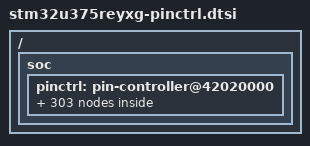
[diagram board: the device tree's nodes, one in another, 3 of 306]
/*
 * NOTE: Autogenerated file using genpinctrl.py
 *
 * SPDX-License-Identifier: Apache-2.0
 */

#include <zephyr/dt-bindings/pinctrl/stm32-pinctrl.h>

/ {
	soc {
		pinctrl: pin-controller@42020000 {

			/* ADC_IN / ADC_INN / ADC_INP */

			/omit-if-no-ref/ adc1_in3_pa0: adc1_in3_pa0 {
				pinmux = <STM32_PINMUX('A', 0, ANALOG)>;
			};

			/omit-if-no-ref/ adc1_in4_pa1: adc1_in4_pa1 {
				pinmux = <STM32_PINMUX('A', 1, ANALOG)>;
			};

			/omit-if-no-ref/ adc1_in5_pa2: adc1_in5_pa2 {
				pinmux = <STM32_PINMUX('A', 2, ANALOG)>;
			};

			/omit-if-no-ref/ adc1_in6_pa3: adc1_in6_pa3 {
				pinmux = <STM32_PINMUX('A', 3, ANALOG)>;
			};

			/omit-if-no-ref/ adc1_in7_pa4: adc1_in7_pa4 {
				pinmux = <STM32_PINMUX('A', 4, ANALOG)>;
			};

			/omit-if-no-ref/ adc1_in8_pa5: adc1_in8_pa5 {
				pinmux = <STM32_PINMUX('A', 5, ANALOG)>;
			};

			/omit-if-no-ref/ adc1_in9_pa6: adc1_in9_pa6 {
				pinmux = <STM32_PINMUX('A', 6, ANALOG)>;
			};

			/omit-if-no-ref/ adc1_in10_pa7: adc1_in10_pa7 {
				pinmux = <STM32_PINMUX('A', 7, ANALOG)>;
			};

			/omit-if-no-ref/ adc1_in13_pb0: adc1_in13_pb0 {
				pinmux = <STM32_PINMUX('B', 0, ANALOG)>;
			};

			/omit-if-no-ref/ adc1_in14_pb1: adc1_in14_pb1 {
				pinmux = <STM32_PINMUX('B', 1, ANALOG)>;
			};

			/omit-if-no-ref/ adc1_in15_pb2: adc1_in15_pb2 {
				pinmux = <STM32_PINMUX('B', 2, ANALOG)>;
			};

			/omit-if-no-ref/ adc2_in3_pa4: adc2_in3_pa4 {
				pinmux = <STM32_PINMUX('A', 4, ANALOG)>;
			};

			/omit-if-no-ref/ adc2_in4_pa5: adc2_in4_pa5 {
				pinmux = <STM32_PINMUX('A', 5, ANALOG)>;
			};

			/omit-if-no-ref/ adc2_in5_pa6: adc2_in5_pa6 {
				pinmux = <STM32_PINMUX('A', 6, ANALOG)>;
			};

			/omit-if-no-ref/ adc2_in6_pa7: adc2_in6_pa7 {
				pinmux = <STM32_PINMUX('A', 7, ANALOG)>;
			};

			/omit-if-no-ref/ adc2_in9_pb0: adc2_in9_pb0 {
				pinmux = <STM32_PINMUX('B', 0, ANALOG)>;
			};

			/omit-if-no-ref/ adc2_in10_pb1: adc2_in10_pb1 {
				pinmux = <STM32_PINMUX('B', 1, ANALOG)>;
			};

			/* Analog */

			/omit-if-no-ref/ analog_pa0: analog_pa0 {
				pinmux = <STM32_PINMUX('A', 0, ANALOG)>;
			};

			/omit-if-no-ref/ analog_pa1: analog_pa1 {
				pinmux = <STM32_PINMUX('A', 1, ANALOG)>;
			};

			/omit-if-no-ref/ analog_pa2: analog_pa2 {
				pinmux = <STM32_PINMUX('A', 2, ANALOG)>;
			};

			/omit-if-no-ref/ analog_pa3: analog_pa3 {
				pinmux = <STM32_PINMUX('A', 3, ANALOG)>;
			};

			/omit-if-no-ref/ analog_pa4: analog_pa4 {
				pinmux = <STM32_PINMUX('A', 4, ANALOG)>;
			};

			/omit-if-no-ref/ analog_pa5: analog_pa5 {
				pinmux = <STM32_PINMUX('A', 5, ANALOG)>;
			};

			/omit-if-no-ref/ analog_pa6: analog_pa6 {
				pinmux = <STM32_PINMUX('A', 6, ANALOG)>;
			};

			/omit-if-no-ref/ analog_pa7: analog_pa7 {
				pinmux = <STM32_PINMUX('A', 7, ANALOG)>;
			};

			/omit-if-no-ref/ analog_pa8: analog_pa8 {
				pinmux = <STM32_PINMUX('A', 8, ANALOG)>;
			};

			/omit-if-no-ref/ analog_pa9: analog_pa9 {
				pinmux = <STM32_PINMUX('A', 9, ANALOG)>;
			};

			/omit-if-no-ref/ analog_pa10: analog_pa10 {
				pinmux = <STM32_PINMUX('A', 10, ANALOG)>;
			};

			/omit-if-no-ref/ analog_pa11: analog_pa11 {
				pinmux = <STM32_PINMUX('A', 11, ANALOG)>;
			};

			/omit-if-no-ref/ analog_pa12: analog_pa12 {
				pinmux = <STM32_PINMUX('A', 12, ANALOG)>;
			};

			/omit-if-no-ref/ analog_pa13: analog_pa13 {
				pinmux = <STM32_PINMUX('A', 13, ANALOG)>;
			};

			/omit-if-no-ref/ analog_pa14: analog_pa14 {
				pinmux = <STM32_PINMUX('A', 14, ANALOG)>;
			};

			/omit-if-no-ref/ analog_pa15: analog_pa15 {
				pinmux = <STM32_PINMUX('A', 15, ANALOG)>;
			};

			/omit-if-no-ref/ analog_pb0: analog_pb0 {
				pinmux = <STM32_PINMUX('B', 0, ANALOG)>;
			};

			/omit-if-no-ref/ analog_pb1: analog_pb1 {
				pinmux = <STM32_PINMUX('B', 1, ANALOG)>;
			};

			/omit-if-no-ref/ analog_pb2: analog_pb2 {
				pinmux = <STM32_PINMUX('B', 2, ANALOG)>;
			};

			/omit-if-no-ref/ analog_pb3: analog_pb3 {
				pinmux = <STM32_PINMUX('B', 3, ANALOG)>;
			};

			/omit-if-no-ref/ analog_pb4: analog_pb4 {
				pinmux = <STM32_PINMUX('B', 4, ANALOG)>;
			};

			/omit-if-no-ref/ analog_pb5: analog_pb5 {
				pinmux = <STM32_PINMUX('B', 5, ANALOG)>;
			};

			/omit-if-no-ref/ analog_pb6: analog_pb6 {
				pinmux = <STM32_PINMUX('B', 6, ANALOG)>;
			};

			/omit-if-no-ref/ analog_pb7: analog_pb7 {
				pinmux = <STM32_PINMUX('B', 7, ANALOG)>;
			};

			/omit-if-no-ref/ analog_pb13: analog_pb13 {
				pinmux = <STM32_PINMUX('B', 13, ANALOG)>;
			};

			/omit-if-no-ref/ analog_pb14: analog_pb14 {
				pinmux = <STM32_PINMUX('B', 14, ANALOG)>;
			};

			/omit-if-no-ref/ analog_pb15: analog_pb15 {
				pinmux = <STM32_PINMUX('B', 15, ANALOG)>;
			};

			/omit-if-no-ref/ analog_pc13: analog_pc13 {
				pinmux = <STM32_PINMUX('C', 13, ANALOG)>;
			};

			/omit-if-no-ref/ analog_pc14: analog_pc14 {
				pinmux = <STM32_PINMUX('C', 14, ANALOG)>;
			};

			/omit-if-no-ref/ analog_pc15: analog_pc15 {
				pinmux = <STM32_PINMUX('C', 15, ANALOG)>;
			};

			/omit-if-no-ref/ analog_pg2: analog_pg2 {
				pinmux = <STM32_PINMUX('G', 2, ANALOG)>;
			};

			/omit-if-no-ref/ analog_pg3: analog_pg3 {
				pinmux = <STM32_PINMUX('G', 3, ANALOG)>;
			};

			/omit-if-no-ref/ analog_pg4: analog_pg4 {
				pinmux = <STM32_PINMUX('G', 4, ANALOG)>;
			};

			/omit-if-no-ref/ analog_pg5: analog_pg5 {
				pinmux = <STM32_PINMUX('G', 5, ANALOG)>;
			};

			/omit-if-no-ref/ analog_pg6: analog_pg6 {
				pinmux = <STM32_PINMUX('G', 6, ANALOG)>;
			};

			/omit-if-no-ref/ analog_pg7: analog_pg7 {
				pinmux = <STM32_PINMUX('G', 7, ANALOG)>;
			};

			/omit-if-no-ref/ analog_pg8: analog_pg8 {
				pinmux = <STM32_PINMUX('G', 8, ANALOG)>;
			};

			/omit-if-no-ref/ analog_pg9: analog_pg9 {
				pinmux = <STM32_PINMUX('G', 9, ANALOG)>;
			};

			/omit-if-no-ref/ analog_pg10: analog_pg10 {
				pinmux = <STM32_PINMUX('G', 10, ANALOG)>;
			};

			/omit-if-no-ref/ analog_pg11: analog_pg11 {
				pinmux = <STM32_PINMUX('G', 11, ANALOG)>;
			};

			/omit-if-no-ref/ analog_pg12: analog_pg12 {
				pinmux = <STM32_PINMUX('G', 12, ANALOG)>;
			};

			/omit-if-no-ref/ analog_pg13: analog_pg13 {
				pinmux = <STM32_PINMUX('G', 13, ANALOG)>;
			};

			/omit-if-no-ref/ analog_pg14: analog_pg14 {
				pinmux = <STM32_PINMUX('G', 14, ANALOG)>;
			};

			/omit-if-no-ref/ analog_pg15: analog_pg15 {
				pinmux = <STM32_PINMUX('G', 15, ANALOG)>;
			};

			/omit-if-no-ref/ analog_ph0: analog_ph0 {
				pinmux = <STM32_PINMUX('H', 0, ANALOG)>;
			};

			/omit-if-no-ref/ analog_ph1: analog_ph1 {
				pinmux = <STM32_PINMUX('H', 1, ANALOG)>;
			};

			/omit-if-no-ref/ analog_ph3: analog_ph3 {
				pinmux = <STM32_PINMUX('H', 3, ANALOG)>;
			};

			/* COMP_IN */

			/omit-if-no-ref/ comp1_inp_pa2: comp1_inp_pa2 {
				pinmux = <STM32_PINMUX('A', 2, ANALOG)>;
			};

			/omit-if-no-ref/ comp1_inp_pa3: comp1_inp_pa3 {
				pinmux = <STM32_PINMUX('A', 3, ANALOG)>;
			};

			/omit-if-no-ref/ comp1_inm_pb1: comp1_inm_pb1 {
				pinmux = <STM32_PINMUX('B', 1, ANALOG)>;
			};

			/omit-if-no-ref/ comp1_inp_pb2: comp1_inp_pb2 {
				pinmux = <STM32_PINMUX('B', 2, ANALOG)>;
			};

			/omit-if-no-ref/ comp2_inm_pb3: comp2_inm_pb3 {
				pinmux = <STM32_PINMUX('B', 3, ANALOG)>;
			};

			/omit-if-no-ref/ comp2_inp_pb4: comp2_inp_pb4 {
				pinmux = <STM32_PINMUX('B', 4, ANALOG)>;
			};

			/omit-if-no-ref/ comp2_inp_pb6: comp2_inp_pb6 {
				pinmux = <STM32_PINMUX('B', 6, ANALOG)>;
			};

			/omit-if-no-ref/ comp2_inm_pb7: comp2_inm_pb7 {
				pinmux = <STM32_PINMUX('B', 7, ANALOG)>;
			};

			/* COMP_OUT */

			/omit-if-no-ref/ comp1_out_pb0: comp1_out_pb0 {
				pinmux = <STM32_PINMUX('B', 0, AF12)>;
			};

			/omit-if-no-ref/ comp2_out_pb5: comp2_out_pb5 {
				pinmux = <STM32_PINMUX('B', 5, AF12)>;
			};

			/* DAC_OUT */

			/omit-if-no-ref/ dac1_out1_pa4: dac1_out1_pa4 {
				pinmux = <STM32_PINMUX('A', 4, ANALOG)>;
			};

			/omit-if-no-ref/ dac1_out2_pa5: dac1_out2_pa5 {
				pinmux = <STM32_PINMUX('A', 5, ANALOG)>;
			};

			/* FDCAN_RX */

			/omit-if-no-ref/ fdcan1_rx_pa11: fdcan1_rx_pa11 {
				pinmux = <STM32_PINMUX('A', 11, AF9)>;
			};

			/* FDCAN_TX */

			/omit-if-no-ref/ fdcan1_tx_pa12: fdcan1_tx_pa12 {
				pinmux = <STM32_PINMUX('A', 12, AF9)>;
			};

			/* I2C_SCL */

			/omit-if-no-ref/ i2c1_scl_pb6: i2c1_scl_pb6 {
				pinmux = <STM32_PINMUX('B', 6, AF4)>;
				bias-pull-up;
				drive-open-drain;
			};

			/omit-if-no-ref/ i2c1_scl_pg14: i2c1_scl_pg14 {
				pinmux = <STM32_PINMUX('G', 14, AF4)>;
				bias-pull-up;
				drive-open-drain;
			};

			/omit-if-no-ref/ i2c2_scl_pb2: i2c2_scl_pb2 {
				pinmux = <STM32_PINMUX('B', 2, AF3)>;
				bias-pull-up;
				drive-open-drain;
			};

			/omit-if-no-ref/ i2c2_scl_pb13: i2c2_scl_pb13 {
				pinmux = <STM32_PINMUX('B', 13, AF4)>;
				bias-pull-up;
				drive-open-drain;
			};

			/omit-if-no-ref/ i2c3_scl_pa7: i2c3_scl_pa7 {
				pinmux = <STM32_PINMUX('A', 7, AF4)>;
				bias-pull-up;
				drive-open-drain;
			};

			/omit-if-no-ref/ i2c3_scl_pg7: i2c3_scl_pg7 {
				pinmux = <STM32_PINMUX('G', 7, AF4)>;
				bias-pull-up;
				drive-open-drain;
			};

			/* I2C_SDA */

			/omit-if-no-ref/ i2c1_sda_pb3: i2c1_sda_pb3 {
				pinmux = <STM32_PINMUX('B', 3, AF4)>;
				bias-pull-up;
				drive-open-drain;
			};

			/omit-if-no-ref/ i2c1_sda_pb7: i2c1_sda_pb7 {
				pinmux = <STM32_PINMUX('B', 7, AF4)>;
				bias-pull-up;
				drive-open-drain;
			};

			/omit-if-no-ref/ i2c1_sda_pg13: i2c1_sda_pg13 {
				pinmux = <STM32_PINMUX('G', 13, AF4)>;
				bias-pull-up;
				drive-open-drain;
			};

			/omit-if-no-ref/ i2c2_sda_pa6: i2c2_sda_pa6 {
				pinmux = <STM32_PINMUX('A', 6, AF4)>;
				bias-pull-up;
				drive-open-drain;
			};

			/omit-if-no-ref/ i2c2_sda_pb14: i2c2_sda_pb14 {
				pinmux = <STM32_PINMUX('B', 14, AF4)>;
				bias-pull-up;
				drive-open-drain;
			};

			/omit-if-no-ref/ i2c3_sda_pb4: i2c3_sda_pb4 {
				pinmux = <STM32_PINMUX('B', 4, AF4)>;
				bias-pull-up;
				drive-open-drain;
			};

			/omit-if-no-ref/ i2c3_sda_pg8: i2c3_sda_pg8 {
				pinmux = <STM32_PINMUX('G', 8, AF4)>;
				bias-pull-up;
				drive-open-drain;
			};

			/* I2C_SMBA */

			/omit-if-no-ref/ i2c1_smba_pa1: i2c1_smba_pa1 {
				pinmux = <STM32_PINMUX('A', 1, AF4)>;
				bias-pull-up;
			};

			/omit-if-no-ref/ i2c1_smba_pa14: i2c1_smba_pa14 {
				pinmux = <STM32_PINMUX('A', 14, AF4)>;
				bias-pull-up;
			};

			/omit-if-no-ref/ i2c1_smba_pb5: i2c1_smba_pb5 {
				pinmux = <STM32_PINMUX('B', 5, AF4)>;
				bias-pull-up;
			};

			/omit-if-no-ref/ i2c1_smba_pg15: i2c1_smba_pg15 {
				pinmux = <STM32_PINMUX('G', 15, AF4)>;
				bias-pull-up;
			};

			/omit-if-no-ref/ i2c2_smba_pa1: i2c2_smba_pa1 {
				pinmux = <STM32_PINMUX('A', 1, AF3)>;
				bias-pull-up;
			};

			/omit-if-no-ref/ i2c2_smba_pa14: i2c2_smba_pa14 {
				pinmux = <STM32_PINMUX('A', 14, AF3)>;
				bias-pull-up;
			};

			/omit-if-no-ref/ i2c3_smba_pa14: i2c3_smba_pa14 {
				pinmux = <STM32_PINMUX('A', 14, AF5)>;
				bias-pull-up;
			};

			/omit-if-no-ref/ i2c3_smba_pb2: i2c3_smba_pb2 {
				pinmux = <STM32_PINMUX('B', 2, AF4)>;
				bias-pull-up;
			};

			/omit-if-no-ref/ i2c3_smba_pg6: i2c3_smba_pg6 {
				pinmux = <STM32_PINMUX('G', 6, AF4)>;
				bias-pull-up;
			};

			/* I3C_SCL */

			/omit-if-no-ref/ i3c1_scl_pa7: i3c1_scl_pa7 {
				pinmux = <STM32_PINMUX('A', 7, AF6)>;
				slew-rate = "very-high-speed";
			};

			/omit-if-no-ref/ i3c1_scl_pb2: i3c1_scl_pb2 {
				pinmux = <STM32_PINMUX('B', 2, AF6)>;
				slew-rate = "very-high-speed";
			};

			/omit-if-no-ref/ i3c1_scl_pb6: i3c1_scl_pb6 {
				pinmux = <STM32_PINMUX('B', 6, AF5)>;
				slew-rate = "very-high-speed";
			};

			/omit-if-no-ref/ i3c1_scl_pb13: i3c1_scl_pb13 {
				pinmux = <STM32_PINMUX('B', 13, AF3)>;
				slew-rate = "very-high-speed";
			};

			/omit-if-no-ref/ i3c1_scl_pg7: i3c1_scl_pg7 {
				pinmux = <STM32_PINMUX('G', 7, AF5)>;
				slew-rate = "very-high-speed";
			};

			/omit-if-no-ref/ i3c2_scl_pb6: i3c2_scl_pb6 {
				pinmux = <STM32_PINMUX('B', 6, AF6)>;
				slew-rate = "very-high-speed";
			};

			/omit-if-no-ref/ i3c2_scl_pb13: i3c2_scl_pb13 {
				pinmux = <STM32_PINMUX('B', 13, AF6)>;
				slew-rate = "very-high-speed";
			};

			/omit-if-no-ref/ i3c2_scl_pg13: i3c2_scl_pg13 {
				pinmux = <STM32_PINMUX('G', 13, AF5)>;
				slew-rate = "very-high-speed";
			};

			/* I3C_SDA */

			/omit-if-no-ref/ i3c1_sda_pa1: i3c1_sda_pa1 {
				pinmux = <STM32_PINMUX('A', 1, AF6)>;
				slew-rate = "very-high-speed";
			};

			/omit-if-no-ref/ i3c1_sda_pa6: i3c1_sda_pa6 {
				pinmux = <STM32_PINMUX('A', 6, AF6)>;
				slew-rate = "very-high-speed";
			};

			/omit-if-no-ref/ i3c1_sda_pg8: i3c1_sda_pg8 {
				pinmux = <STM32_PINMUX('G', 8, AF5)>;
				slew-rate = "very-high-speed";
			};

			/omit-if-no-ref/ i3c1_sda_ph3: i3c1_sda_ph3 {
				pinmux = <STM32_PINMUX('H', 3, AF3)>;
				slew-rate = "very-high-speed";
			};

			/omit-if-no-ref/ i3c2_sda_pa6: i3c2_sda_pa6 {
				pinmux = <STM32_PINMUX('A', 6, AF3)>;
				slew-rate = "very-high-speed";
			};

			/omit-if-no-ref/ i3c2_sda_pb14: i3c2_sda_pb14 {
				pinmux = <STM32_PINMUX('B', 14, AF6)>;
				slew-rate = "very-high-speed";
			};

			/omit-if-no-ref/ i3c2_sda_pg14: i3c2_sda_pg14 {
				pinmux = <STM32_PINMUX('G', 14, AF5)>;
				slew-rate = "very-high-speed";
			};

			/omit-if-no-ref/ i3c2_sda_ph3: i3c2_sda_ph3 {
				pinmux = <STM32_PINMUX('H', 3, AF6)>;
				slew-rate = "very-high-speed";
			};

			/* JTAG PORT */

			/omit-if-no-ref/ debug_jtms_swdio_pa13: debug_jtms_swdio_pa13 {
				pinmux = <STM32_PINMUX('A', 13, AF0)>;
			};

			/omit-if-no-ref/ debug_jtck_swclk_pa14: debug_jtck_swclk_pa14 {
				pinmux = <STM32_PINMUX('A', 14, AF0)>;
			};

			/omit-if-no-ref/ debug_jtdi_pa15: debug_jtdi_pa15 {
				pinmux = <STM32_PINMUX('A', 15, AF0)>;
			};

			/omit-if-no-ref/ debug_jtdo_swo_pb3: debug_jtdo_swo_pb3 {
				pinmux = <STM32_PINMUX('B', 3, AF0)>;
			};

			/omit-if-no-ref/ debug_njtrst_pb4: debug_njtrst_pb4 {
				pinmux = <STM32_PINMUX('B', 4, AF0)>;
			};

			/* OCTOSPI */

			/omit-if-no-ref/ octospi1_dqs_pa1: octospi1_dqs_pa1 {
				pinmux = <STM32_PINMUX('A', 1, AF10)>;
				slew-rate = "very-high-speed";
			};

			/omit-if-no-ref/ octospi1_ncs_pa2: octospi1_ncs_pa2 {
				pinmux = <STM32_PINMUX('A', 2, AF10)>;
				slew-rate = "very-high-speed";
			};

			/omit-if-no-ref/ octospi1_clk_pa3: octospi1_clk_pa3 {
				pinmux = <STM32_PINMUX('A', 3, AF10)>;
				slew-rate = "very-high-speed";
			};

			/omit-if-no-ref/ octospi1_ncs_pa4: octospi1_ncs_pa4 {
				pinmux = <STM32_PINMUX('A', 4, AF3)>;
				slew-rate = "very-high-speed";
			};

			/omit-if-no-ref/ octospi1_io3_pa6: octospi1_io3_pa6 {
				pinmux = <STM32_PINMUX('A', 6, AF10)>;
				slew-rate = "very-high-speed";
			};

			/omit-if-no-ref/ octospi1_io2_pa7: octospi1_io2_pa7 {
				pinmux = <STM32_PINMUX('A', 7, AF10)>;
				slew-rate = "very-high-speed";
			};

			/omit-if-no-ref/ octospi1_io1_pb0: octospi1_io1_pb0 {
				pinmux = <STM32_PINMUX('B', 0, AF10)>;
				slew-rate = "very-high-speed";
			};

			/omit-if-no-ref/ octospi1_io0_pb1: octospi1_io0_pb1 {
				pinmux = <STM32_PINMUX('B', 1, AF10)>;
				slew-rate = "very-high-speed";
			};

			/omit-if-no-ref/ octospi1_dqs_pb2: octospi1_dqs_pb2 {
				pinmux = <STM32_PINMUX('B', 2, AF10)>;
				slew-rate = "very-high-speed";
			};

			/omit-if-no-ref/ octospi1_io4_pb4: octospi1_io4_pb4 {
				pinmux = <STM32_PINMUX('B', 4, AF10)>;
				slew-rate = "very-high-speed";
			};

			/omit-if-no-ref/ octospi1_nclk_pb5: octospi1_nclk_pb5 {
				pinmux = <STM32_PINMUX('B', 5, AF3)>;
				slew-rate = "very-high-speed";
			};

			/omit-if-no-ref/ octospi1_io5_pb6: octospi1_io5_pb6 {
				pinmux = <STM32_PINMUX('B', 6, AF10)>;
				slew-rate = "very-high-speed";
			};

			/omit-if-no-ref/ octospi1_io6_pb7: octospi1_io6_pb7 {
				pinmux = <STM32_PINMUX('B', 7, AF10)>;
				slew-rate = "very-high-speed";
			};

			/omit-if-no-ref/ octospi1_io3_pg2: octospi1_io3_pg2 {
				pinmux = <STM32_PINMUX('G', 2, AF10)>;
				slew-rate = "very-high-speed";
			};

			/omit-if-no-ref/ octospi1_io4_pg3: octospi1_io4_pg3 {
				pinmux = <STM32_PINMUX('G', 3, AF10)>;
				slew-rate = "very-high-speed";
			};

			/omit-if-no-ref/ octospi1_io0_pg4: octospi1_io0_pg4 {
				pinmux = <STM32_PINMUX('G', 4, AF10)>;
				slew-rate = "very-high-speed";
			};

			/omit-if-no-ref/ octospi1_io1_pg5: octospi1_io1_pg5 {
				pinmux = <STM32_PINMUX('G', 5, AF10)>;
				slew-rate = "very-high-speed";
			};

			/omit-if-no-ref/ octospi1_dqs_pg6: octospi1_dqs_pg6 {
				pinmux = <STM32_PINMUX('G', 6, AF3)>;
				slew-rate = "very-high-speed";
			};

			/omit-if-no-ref/ octospi1_io2_pg8: octospi1_io2_pg8 {
				pinmux = <STM32_PINMUX('G', 8, AF10)>;
				slew-rate = "very-high-speed";
			};

			/omit-if-no-ref/ octospi1_io6_pg9: octospi1_io6_pg9 {
				pinmux = <STM32_PINMUX('G', 9, AF10)>;
				slew-rate = "very-high-speed";
			};

			/omit-if-no-ref/ octospi1_io7_pg10: octospi1_io7_pg10 {
				pinmux = <STM32_PINMUX('G', 10, AF10)>;
				slew-rate = "very-high-speed";
			};

			/omit-if-no-ref/ octospi1_io5_pg11: octospi1_io5_pg11 {
				pinmux = <STM32_PINMUX('G', 11, AF3)>;
				slew-rate = "very-high-speed";
			};

			/omit-if-no-ref/ octospi1_ncs_pg12: octospi1_ncs_pg12 {
				pinmux = <STM32_PINMUX('G', 12, AF10)>;
				slew-rate = "very-high-speed";
			};

			/omit-if-no-ref/ octospi1_clk_pg13: octospi1_clk_pg13 {
				pinmux = <STM32_PINMUX('G', 13, AF10)>;
				slew-rate = "very-high-speed";
			};

			/omit-if-no-ref/ octospi1_nclk_pg14: octospi1_nclk_pg14 {
				pinmux = <STM32_PINMUX('G', 14, AF10)>;
				slew-rate = "very-high-speed";
			};

			/omit-if-no-ref/ octospi1_dqs_pg15: octospi1_dqs_pg15 {
				pinmux = <STM32_PINMUX('G', 15, AF10)>;
				slew-rate = "very-high-speed";
			};

			/* OPAMP */

			/omit-if-no-ref/ opamp1_vinp_pa0: opamp1_vinp_pa0 {
				pinmux = <STM32_PINMUX('A', 0, ANALOG)>;
			};

			/omit-if-no-ref/ opamp1_vinm_pa1: opamp1_vinm_pa1 {
				pinmux = <STM32_PINMUX('A', 1, ANALOG)>;
			};

			/omit-if-no-ref/ opamp1_vout_pa3: opamp1_vout_pa3 {
				pinmux = <STM32_PINMUX('A', 3, ANALOG)>;
			};

			/omit-if-no-ref/ opamp2_vinp_pa6: opamp2_vinp_pa6 {
				pinmux = <STM32_PINMUX('A', 6, ANALOG)>;
			};

			/omit-if-no-ref/ opamp2_vinm_pa7: opamp2_vinm_pa7 {
				pinmux = <STM32_PINMUX('A', 7, ANALOG)>;
			};

			/omit-if-no-ref/ opamp2_vout_pb0: opamp2_vout_pb0 {
				pinmux = <STM32_PINMUX('B', 0, ANALOG)>;
			};

			/* RCC_MCO */

			/omit-if-no-ref/ rcc_mco_pa8: rcc_mco_pa8 {
				pinmux = <STM32_PINMUX('A', 8, AF0)>;
				slew-rate = "very-high-speed";
			};

			/omit-if-no-ref/ rcc_mco2_pa8: rcc_mco2_pa8 {
				pinmux = <STM32_PINMUX('A', 8, AF11)>;
				slew-rate = "very-high-speed";
			};

			/omit-if-no-ref/ rcc_mco_pa9: rcc_mco_pa9 {
				pinmux = <STM32_PINMUX('A', 9, AF0)>;
				slew-rate = "very-high-speed";
			};

			/omit-if-no-ref/ rcc_mco2_pa10: rcc_mco2_pa10 {
				pinmux = <STM32_PINMUX('A', 10, AF11)>;
				slew-rate = "very-high-speed";
			};

			/* SAI */

			/omit-if-no-ref/ sai1_ck1_pa3: sai1_ck1_pa3 {
				pinmux = <STM32_PINMUX('A', 3, AF3)>;
			};

			/omit-if-no-ref/ sai1_mclk_a_pa3: sai1_mclk_a_pa3 {
				pinmux = <STM32_PINMUX('A', 3, AF13)>;
			};

			/omit-if-no-ref/ sai1_fs_b_pa4: sai1_fs_b_pa4 {
				pinmux = <STM32_PINMUX('A', 4, AF13)>;
			};

			/omit-if-no-ref/ sai1_ck2_pa8: sai1_ck2_pa8 {
				pinmux = <STM32_PINMUX('A', 8, AF3)>;
			};

			/omit-if-no-ref/ sai1_sck_a_pa8: sai1_sck_a_pa8 {
				pinmux = <STM32_PINMUX('A', 8, AF13)>;
			};

			/omit-if-no-ref/ sai1_fs_a_pa9: sai1_fs_a_pa9 {
				pinmux = <STM32_PINMUX('A', 9, AF13)>;
			};

			/omit-if-no-ref/ sai1_d1_pa10: sai1_d1_pa10 {
				pinmux = <STM32_PINMUX('A', 10, AF3)>;
			};

			/omit-if-no-ref/ sai1_sd_a_pa10: sai1_sd_a_pa10 {
				pinmux = <STM32_PINMUX('A', 10, AF13)>;
			};

			/omit-if-no-ref/ sai1_sd_b_pa13: sai1_sd_b_pa13 {
				pinmux = <STM32_PINMUX('A', 13, AF13)>;
			};

			/omit-if-no-ref/ sai1_fs_b_pa14: sai1_fs_b_pa14 {
				pinmux = <STM32_PINMUX('A', 14, AF13)>;
			};

			/omit-if-no-ref/ sai1_d2_pa15: sai1_d2_pa15 {
				pinmux = <STM32_PINMUX('A', 15, AF3)>;
			};

			/omit-if-no-ref/ sai1_sck_b_pb3: sai1_sck_b_pb3 {
				pinmux = <STM32_PINMUX('B', 3, AF13)>;
			};

			/omit-if-no-ref/ sai1_mclk_b_pb4: sai1_mclk_b_pb4 {
				pinmux = <STM32_PINMUX('B', 4, AF13)>;
			};

			/omit-if-no-ref/ sai1_sd_b_pb5: sai1_sd_b_pb5 {
				pinmux = <STM32_PINMUX('B', 5, AF13)>;
			};

			/omit-if-no-ref/ sai1_fs_b_pb6: sai1_fs_b_pb6 {
				pinmux = <STM32_PINMUX('B', 6, AF13)>;
			};

			/omit-if-no-ref/ sai1_d3_pb15: sai1_d3_pb15 {
				pinmux = <STM32_PINMUX('B', 15, AF3)>;
			};

			/omit-if-no-ref/ sai1_ck1_pg7: sai1_ck1_pg7 {
				pinmux = <STM32_PINMUX('G', 7, AF3)>;
			};

			/omit-if-no-ref/ sai1_mclk_a_pg7: sai1_mclk_a_pg7 {
				pinmux = <STM32_PINMUX('G', 7, AF13)>;
			};

			/* SPI_MISO */

			/omit-if-no-ref/ spi1_miso_pa6: spi1_miso_pa6 {
				pinmux = <STM32_PINMUX('A', 6, AF5)>;
				bias-pull-down;
			};

			/omit-if-no-ref/ spi1_miso_pa11: spi1_miso_pa11 {
				pinmux = <STM32_PINMUX('A', 11, AF5)>;
				bias-pull-down;
			};

			/omit-if-no-ref/ spi1_miso_pb4: spi1_miso_pb4 {
				pinmux = <STM32_PINMUX('B', 4, AF5)>;
				bias-pull-down;
			};

			/omit-if-no-ref/ spi1_miso_pg3: spi1_miso_pg3 {
				pinmux = <STM32_PINMUX('G', 3, AF5)>;
				bias-pull-down;
			};

			/omit-if-no-ref/ spi2_miso_pb14: spi2_miso_pb14 {
				pinmux = <STM32_PINMUX('B', 14, AF5)>;
				bias-pull-down;
			};

			/omit-if-no-ref/ spi3_miso_pb4: spi3_miso_pb4 {
				pinmux = <STM32_PINMUX('B', 4, AF6)>;
				bias-pull-down;
			};

			/omit-if-no-ref/ spi3_miso_pg10: spi3_miso_pg10 {
				pinmux = <STM32_PINMUX('G', 10, AF6)>;
				bias-pull-down;
			};

			/* SPI_MOSI */

			/omit-if-no-ref/ spi1_mosi_pa7: spi1_mosi_pa7 {
				pinmux = <STM32_PINMUX('A', 7, AF5)>;
				bias-pull-down;
			};

			/omit-if-no-ref/ spi1_mosi_pa12: spi1_mosi_pa12 {
				pinmux = <STM32_PINMUX('A', 12, AF5)>;
				bias-pull-down;
			};

			/omit-if-no-ref/ spi1_mosi_pb5: spi1_mosi_pb5 {
				pinmux = <STM32_PINMUX('B', 5, AF5)>;
				bias-pull-down;
			};

			/omit-if-no-ref/ spi1_mosi_pg4: spi1_mosi_pg4 {
				pinmux = <STM32_PINMUX('G', 4, AF5)>;
				bias-pull-down;
			};

			/omit-if-no-ref/ spi2_mosi_pb15: spi2_mosi_pb15 {
				pinmux = <STM32_PINMUX('B', 15, AF5)>;
				bias-pull-down;
			};

			/omit-if-no-ref/ spi3_mosi_pb5: spi3_mosi_pb5 {
				pinmux = <STM32_PINMUX('B', 5, AF6)>;
				bias-pull-down;
			};

			/omit-if-no-ref/ spi3_mosi_pg11: spi3_mosi_pg11 {
				pinmux = <STM32_PINMUX('G', 11, AF6)>;
				bias-pull-down;
			};

			/* SPI_NSS */

			/omit-if-no-ref/ spi1_nss_pa4: spi1_nss_pa4 {
				pinmux = <STM32_PINMUX('A', 4, AF5)>;
				bias-pull-up;
			};

			/omit-if-no-ref/ spi1_nss_pa15: spi1_nss_pa15 {
				pinmux = <STM32_PINMUX('A', 15, AF5)>;
				bias-pull-up;
			};

			/omit-if-no-ref/ spi1_nss_pb0: spi1_nss_pb0 {
				pinmux = <STM32_PINMUX('B', 0, AF5)>;
				bias-pull-up;
			};

			/omit-if-no-ref/ spi1_nss_pg5: spi1_nss_pg5 {
				pinmux = <STM32_PINMUX('G', 5, AF5)>;
				bias-pull-up;
			};

			/omit-if-no-ref/ spi3_nss_pa4: spi3_nss_pa4 {
				pinmux = <STM32_PINMUX('A', 4, AF6)>;
				bias-pull-up;
			};

			/omit-if-no-ref/ spi3_nss_pa15: spi3_nss_pa15 {
				pinmux = <STM32_PINMUX('A', 15, AF6)>;
				bias-pull-up;
			};

			/omit-if-no-ref/ spi3_nss_pg12: spi3_nss_pg12 {
				pinmux = <STM32_PINMUX('G', 12, AF6)>;
				bias-pull-up;
			};

			/* SPI_SCK */

			/omit-if-no-ref/ spi1_sck_pa1: spi1_sck_pa1 {
				pinmux = <STM32_PINMUX('A', 1, AF5)>;
				bias-pull-down;
				slew-rate = "very-high-speed";
			};

			/omit-if-no-ref/ spi1_sck_pa5: spi1_sck_pa5 {
				pinmux = <STM32_PINMUX('A', 5, AF5)>;
				bias-pull-down;
				slew-rate = "very-high-speed";
			};

			/omit-if-no-ref/ spi1_sck_pb3: spi1_sck_pb3 {
				pinmux = <STM32_PINMUX('B', 3, AF5)>;
				bias-pull-down;
				slew-rate = "very-high-speed";
			};

			/omit-if-no-ref/ spi1_sck_pg2: spi1_sck_pg2 {
				pinmux = <STM32_PINMUX('G', 2, AF5)>;
				bias-pull-down;
				slew-rate = "very-high-speed";
			};

			/omit-if-no-ref/ spi2_sck_pa9: spi2_sck_pa9 {
				pinmux = <STM32_PINMUX('A', 9, AF3)>;
				bias-pull-down;
				slew-rate = "very-high-speed";
			};

			/omit-if-no-ref/ spi2_sck_pb13: spi2_sck_pb13 {
				pinmux = <STM32_PINMUX('B', 13, AF5)>;
				bias-pull-down;
				slew-rate = "very-high-speed";
			};

			/omit-if-no-ref/ spi3_sck_pb3: spi3_sck_pb3 {
				pinmux = <STM32_PINMUX('B', 3, AF6)>;
				bias-pull-down;
				slew-rate = "very-high-speed";
			};

			/omit-if-no-ref/ spi3_sck_pg9: spi3_sck_pg9 {
				pinmux = <STM32_PINMUX('G', 9, AF6)>;
				bias-pull-down;
				slew-rate = "very-high-speed";
			};

			/* TIM_BKIN */

			/omit-if-no-ref/ tim1_bkin_pa6: tim1_bkin_pa6 {
				pinmux = <STM32_PINMUX('A', 6, AF1)>;
			};

			/omit-if-no-ref/ tim1_bkin2_pa11: tim1_bkin2_pa11 {
				pinmux = <STM32_PINMUX('A', 11, AF2)>;
			};

			/omit-if-no-ref/ tim15_bkin_pa9: tim15_bkin_pa9 {
				pinmux = <STM32_PINMUX('A', 9, AF14)>;
			};

			/omit-if-no-ref/ tim16_bkin_pb5: tim16_bkin_pb5 {
				pinmux = <STM32_PINMUX('B', 5, AF14)>;
			};

			/omit-if-no-ref/ tim17_bkin_pa10: tim17_bkin_pa10 {
				pinmux = <STM32_PINMUX('A', 10, AF14)>;
			};

			/omit-if-no-ref/ tim17_bkin_pb4: tim17_bkin_pb4 {
				pinmux = <STM32_PINMUX('B', 4, AF14)>;
			};

			/* TIM_CH / TIM_CHN */

			/omit-if-no-ref/ tim1_ch1n_pa7: tim1_ch1n_pa7 {
				pinmux = <STM32_PINMUX('A', 7, AF1)>;
			};

			/omit-if-no-ref/ tim1_ch1_pa8: tim1_ch1_pa8 {
				pinmux = <STM32_PINMUX('A', 8, AF1)>;
			};

			/omit-if-no-ref/ tim1_ch2_pa9: tim1_ch2_pa9 {
				pinmux = <STM32_PINMUX('A', 9, AF1)>;
			};

			/omit-if-no-ref/ tim1_ch3_pa10: tim1_ch3_pa10 {
				pinmux = <STM32_PINMUX('A', 10, AF1)>;
			};

			/omit-if-no-ref/ tim1_ch4_pa11: tim1_ch4_pa11 {
				pinmux = <STM32_PINMUX('A', 11, AF1)>;
			};

			/omit-if-no-ref/ tim1_ch2n_pb0: tim1_ch2n_pb0 {
				pinmux = <STM32_PINMUX('B', 0, AF1)>;
			};

			/omit-if-no-ref/ tim1_ch3n_pb1: tim1_ch3n_pb1 {
				pinmux = <STM32_PINMUX('B', 1, AF1)>;
			};

			/omit-if-no-ref/ tim1_ch1n_pb13: tim1_ch1n_pb13 {
				pinmux = <STM32_PINMUX('B', 13, AF1)>;
			};

			/omit-if-no-ref/ tim1_ch2n_pb14: tim1_ch2n_pb14 {
				pinmux = <STM32_PINMUX('B', 14, AF1)>;
			};

			/omit-if-no-ref/ tim1_ch3n_pb15: tim1_ch3n_pb15 {
				pinmux = <STM32_PINMUX('B', 15, AF1)>;
			};

			/omit-if-no-ref/ tim2_ch1_pa0: tim2_ch1_pa0 {
				pinmux = <STM32_PINMUX('A', 0, AF1)>;
			};

			/omit-if-no-ref/ tim2_ch2_pa1: tim2_ch2_pa1 {
				pinmux = <STM32_PINMUX('A', 1, AF1)>;
			};

			/omit-if-no-ref/ tim2_ch3_pa2: tim2_ch3_pa2 {
				pinmux = <STM32_PINMUX('A', 2, AF1)>;
			};

			/omit-if-no-ref/ tim2_ch4_pa3: tim2_ch4_pa3 {
				pinmux = <STM32_PINMUX('A', 3, AF1)>;
			};

			/omit-if-no-ref/ tim2_ch1_pa5: tim2_ch1_pa5 {
				pinmux = <STM32_PINMUX('A', 5, AF1)>;
			};

			/omit-if-no-ref/ tim2_ch1_pa15: tim2_ch1_pa15 {
				pinmux = <STM32_PINMUX('A', 15, AF1)>;
			};

			/omit-if-no-ref/ tim2_ch2_pb3: tim2_ch2_pb3 {
				pinmux = <STM32_PINMUX('B', 3, AF1)>;
			};

			/omit-if-no-ref/ tim3_ch1_pa6: tim3_ch1_pa6 {
				pinmux = <STM32_PINMUX('A', 6, AF2)>;
			};

			/omit-if-no-ref/ tim3_ch2_pa7: tim3_ch2_pa7 {
				pinmux = <STM32_PINMUX('A', 7, AF2)>;
			};

			/omit-if-no-ref/ tim3_ch3_pb0: tim3_ch3_pb0 {
				pinmux = <STM32_PINMUX('B', 0, AF2)>;
			};

			/omit-if-no-ref/ tim3_ch4_pb1: tim3_ch4_pb1 {
				pinmux = <STM32_PINMUX('B', 1, AF2)>;
			};

			/omit-if-no-ref/ tim3_ch1_pb4: tim3_ch1_pb4 {
				pinmux = <STM32_PINMUX('B', 4, AF2)>;
			};

			/omit-if-no-ref/ tim3_ch2_pb5: tim3_ch2_pb5 {
				pinmux = <STM32_PINMUX('B', 5, AF2)>;
			};

			/omit-if-no-ref/ tim4_ch1_pb6: tim4_ch1_pb6 {
				pinmux = <STM32_PINMUX('B', 6, AF2)>;
			};

			/omit-if-no-ref/ tim4_ch2_pb7: tim4_ch2_pb7 {
				pinmux = <STM32_PINMUX('B', 7, AF2)>;
			};

			/omit-if-no-ref/ tim4_ch4_ph3: tim4_ch4_ph3 {
				pinmux = <STM32_PINMUX('H', 3, AF2)>;
			};

			/omit-if-no-ref/ tim15_ch1n_pa1: tim15_ch1n_pa1 {
				pinmux = <STM32_PINMUX('A', 1, AF14)>;
			};

			/omit-if-no-ref/ tim15_ch1_pa2: tim15_ch1_pa2 {
				pinmux = <STM32_PINMUX('A', 2, AF14)>;
			};

			/omit-if-no-ref/ tim15_ch2_pa3: tim15_ch2_pa3 {
				pinmux = <STM32_PINMUX('A', 3, AF14)>;
			};

			/omit-if-no-ref/ tim15_ch1n_pb13: tim15_ch1n_pb13 {
				pinmux = <STM32_PINMUX('B', 13, AF14)>;
			};

			/omit-if-no-ref/ tim15_ch1_pb14: tim15_ch1_pb14 {
				pinmux = <STM32_PINMUX('B', 14, AF14)>;
			};

			/omit-if-no-ref/ tim15_ch2_pb15: tim15_ch2_pb15 {
				pinmux = <STM32_PINMUX('B', 15, AF14)>;
			};

			/omit-if-no-ref/ tim15_ch1n_pg9: tim15_ch1n_pg9 {
				pinmux = <STM32_PINMUX('G', 9, AF14)>;
			};

			/omit-if-no-ref/ tim15_ch1_pg10: tim15_ch1_pg10 {
				pinmux = <STM32_PINMUX('G', 10, AF14)>;
			};

			/omit-if-no-ref/ tim15_ch2_pg11: tim15_ch2_pg11 {
				pinmux = <STM32_PINMUX('G', 11, AF14)>;
			};

			/omit-if-no-ref/ tim16_ch1_pa6: tim16_ch1_pa6 {
				pinmux = <STM32_PINMUX('A', 6, AF14)>;
			};

			/omit-if-no-ref/ tim16_ch1n_pb6: tim16_ch1n_pb6 {
				pinmux = <STM32_PINMUX('B', 6, AF14)>;
			};

			/omit-if-no-ref/ tim17_ch1_pa7: tim17_ch1_pa7 {
				pinmux = <STM32_PINMUX('A', 7, AF14)>;
			};

			/omit-if-no-ref/ tim17_ch1n_pb7: tim17_ch1n_pb7 {
				pinmux = <STM32_PINMUX('B', 7, AF14)>;
			};

			/* TSC */

			/omit-if-no-ref/ tsc_g3_io1_pa15: tsc_g3_io1_pa15 {
				pinmux = <STM32_PINMUX('A', 15, AF9)>;
			};

			/omit-if-no-ref/ tsc_g2_io1_pb4: tsc_g2_io1_pb4 {
				pinmux = <STM32_PINMUX('B', 4, AF9)>;
			};

			/omit-if-no-ref/ tsc_g2_io2_pb5: tsc_g2_io2_pb5 {
				pinmux = <STM32_PINMUX('B', 5, AF9)>;
			};

			/omit-if-no-ref/ tsc_g2_io3_pb6: tsc_g2_io3_pb6 {
				pinmux = <STM32_PINMUX('B', 6, AF9)>;
			};

			/omit-if-no-ref/ tsc_g2_io4_pb7: tsc_g2_io4_pb7 {
				pinmux = <STM32_PINMUX('B', 7, AF9)>;
			};

			/omit-if-no-ref/ tsc_g1_io2_pb13: tsc_g1_io2_pb13 {
				pinmux = <STM32_PINMUX('B', 13, AF9)>;
			};

			/omit-if-no-ref/ tsc_g1_io3_pb14: tsc_g1_io3_pb14 {
				pinmux = <STM32_PINMUX('B', 14, AF9)>;
			};

			/omit-if-no-ref/ tsc_g1_io4_pb15: tsc_g1_io4_pb15 {
				pinmux = <STM32_PINMUX('B', 15, AF9)>;
			};

			/* UART_CTS / USART_CTS / LPUART_CTS */

			/omit-if-no-ref/ lpuart1_cts_pa6: lpuart1_cts_pa6 {
				pinmux = <STM32_PINMUX('A', 6, AF8)>;
				bias-pull-up;
			};

			/omit-if-no-ref/ usart1_cts_pa11: usart1_cts_pa11 {
				pinmux = <STM32_PINMUX('A', 11, AF7)>;
				bias-pull-up;
			};

			/omit-if-no-ref/ usart1_cts_pb4: usart1_cts_pb4 {
				pinmux = <STM32_PINMUX('B', 4, AF7)>;
				bias-pull-up;
			};

			/omit-if-no-ref/ lpuart1_cts_pb13: lpuart1_cts_pb13 {
				pinmux = <STM32_PINMUX('B', 13, AF8)>;
				bias-pull-up;
			};

			/omit-if-no-ref/ lpuart1_cts_pg5: lpuart1_cts_pg5 {
				pinmux = <STM32_PINMUX('G', 5, AF8)>;
				bias-pull-up;
			};

			/omit-if-no-ref/ usart1_cts_pg11: usart1_cts_pg11 {
				pinmux = <STM32_PINMUX('G', 11, AF7)>;
				bias-pull-up;
			};

			/omit-if-no-ref/ usart3_cts_pa6: usart3_cts_pa6 {
				pinmux = <STM32_PINMUX('A', 6, AF7)>;
				bias-pull-up;
			};

			/omit-if-no-ref/ usart3_cts_pb13: usart3_cts_pb13 {
				pinmux = <STM32_PINMUX('B', 13, AF7)>;
				bias-pull-up;
			};

			/omit-if-no-ref/ uart4_cts_pb7: uart4_cts_pb7 {
				pinmux = <STM32_PINMUX('B', 7, AF8)>;
				bias-pull-up;
			};

			/* UART_DE / USART_DE / LPUART_DE */

			/omit-if-no-ref/ usart1_de_pa12: usart1_de_pa12 {
				pinmux = <STM32_PINMUX('A', 12, AF7)>;
				drive-push-pull;
			};

			/omit-if-no-ref/ lpuart1_de_pb1: lpuart1_de_pb1 {
				pinmux = <STM32_PINMUX('B', 1, AF8)>;
				drive-push-pull;
			};

			/omit-if-no-ref/ usart1_de_pb3: usart1_de_pb3 {
				pinmux = <STM32_PINMUX('B', 3, AF7)>;
				drive-push-pull;
			};

			/omit-if-no-ref/ lpuart1_de_pg6: lpuart1_de_pg6 {
				pinmux = <STM32_PINMUX('G', 6, AF8)>;
				drive-push-pull;
			};

			/omit-if-no-ref/ usart1_de_pg12: usart1_de_pg12 {
				pinmux = <STM32_PINMUX('G', 12, AF7)>;
				drive-push-pull;
			};

			/omit-if-no-ref/ usart3_de_pa15: usart3_de_pa15 {
				pinmux = <STM32_PINMUX('A', 15, AF7)>;
				drive-push-pull;
			};

			/omit-if-no-ref/ usart3_de_pb1: usart3_de_pb1 {
				pinmux = <STM32_PINMUX('B', 1, AF7)>;
				drive-push-pull;
			};

			/omit-if-no-ref/ usart3_de_pb14: usart3_de_pb14 {
				pinmux = <STM32_PINMUX('B', 14, AF7)>;
				drive-push-pull;
			};

			/omit-if-no-ref/ uart4_de_pa15: uart4_de_pa15 {
				pinmux = <STM32_PINMUX('A', 15, AF8)>;
				drive-push-pull;
			};

			/* UART_RTS / USART_RTS / LPUART_RTS */

			/omit-if-no-ref/ usart1_rts_pa12: usart1_rts_pa12 {
				pinmux = <STM32_PINMUX('A', 12, AF7)>;
				drive-push-pull;
			};

			/omit-if-no-ref/ lpuart1_rts_pb1: lpuart1_rts_pb1 {
				pinmux = <STM32_PINMUX('B', 1, AF8)>;
				drive-push-pull;
			};

			/omit-if-no-ref/ usart1_rts_pb3: usart1_rts_pb3 {
				pinmux = <STM32_PINMUX('B', 3, AF7)>;
				drive-push-pull;
			};

			/omit-if-no-ref/ lpuart1_rts_pg6: lpuart1_rts_pg6 {
				pinmux = <STM32_PINMUX('G', 6, AF8)>;
				drive-push-pull;
			};

			/omit-if-no-ref/ usart1_rts_pg12: usart1_rts_pg12 {
				pinmux = <STM32_PINMUX('G', 12, AF7)>;
				drive-push-pull;
			};

			/omit-if-no-ref/ usart3_rts_pa15: usart3_rts_pa15 {
				pinmux = <STM32_PINMUX('A', 15, AF7)>;
				drive-push-pull;
			};

			/omit-if-no-ref/ usart3_rts_pb1: usart3_rts_pb1 {
				pinmux = <STM32_PINMUX('B', 1, AF7)>;
				drive-push-pull;
			};

			/omit-if-no-ref/ usart3_rts_pb14: usart3_rts_pb14 {
				pinmux = <STM32_PINMUX('B', 14, AF7)>;
				drive-push-pull;
			};

			/omit-if-no-ref/ uart4_rts_pa15: uart4_rts_pa15 {
				pinmux = <STM32_PINMUX('A', 15, AF8)>;
				drive-push-pull;
			};

			/* UART_RX / USART_RX / LPUART_RX */

			/omit-if-no-ref/ lpuart1_rx_pa3: lpuart1_rx_pa3 {
				pinmux = <STM32_PINMUX('A', 3, AF8)>;
			};

			/omit-if-no-ref/ lpuart1_rx_pa10: lpuart1_rx_pa10 {
				pinmux = <STM32_PINMUX('A', 10, AF8)>;
			};

			/omit-if-no-ref/ usart1_rx_pa10: usart1_rx_pa10 {
				pinmux = <STM32_PINMUX('A', 10, AF7)>;
			};

			/omit-if-no-ref/ usart1_rx_pb7: usart1_rx_pb7 {
				pinmux = <STM32_PINMUX('B', 7, AF7)>;
			};

			/omit-if-no-ref/ lpuart1_rx_pg8: lpuart1_rx_pg8 {
				pinmux = <STM32_PINMUX('G', 8, AF8)>;
			};

			/omit-if-no-ref/ usart1_rx_pg10: usart1_rx_pg10 {
				pinmux = <STM32_PINMUX('G', 10, AF7)>;
			};

			/omit-if-no-ref/ usart3_rx_pa5: usart3_rx_pa5 {
				pinmux = <STM32_PINMUX('A', 5, AF7)>;
			};

			/omit-if-no-ref/ uart4_rx_pa1: uart4_rx_pa1 {
				pinmux = <STM32_PINMUX('A', 1, AF8)>;
			};

			/* UART_TX / USART_TX / LPUART_TX */

			/omit-if-no-ref/ lpuart1_tx_pa2: lpuart1_tx_pa2 {
				pinmux = <STM32_PINMUX('A', 2, AF8)>;
				bias-pull-up;
			};

			/omit-if-no-ref/ lpuart1_tx_pa9: lpuart1_tx_pa9 {
				pinmux = <STM32_PINMUX('A', 9, AF8)>;
				bias-pull-up;
			};

			/omit-if-no-ref/ usart1_tx_pa9: usart1_tx_pa9 {
				pinmux = <STM32_PINMUX('A', 9, AF7)>;
				bias-pull-up;
			};

			/omit-if-no-ref/ usart1_tx_pb6: usart1_tx_pb6 {
				pinmux = <STM32_PINMUX('B', 6, AF7)>;
				bias-pull-up;
			};

			/omit-if-no-ref/ lpuart1_tx_pg7: lpuart1_tx_pg7 {
				pinmux = <STM32_PINMUX('G', 7, AF8)>;
				bias-pull-up;
			};

			/omit-if-no-ref/ usart1_tx_pg9: usart1_tx_pg9 {
				pinmux = <STM32_PINMUX('G', 9, AF7)>;
				bias-pull-up;
			};

			/omit-if-no-ref/ usart3_tx_pa7: usart3_tx_pa7 {
				pinmux = <STM32_PINMUX('A', 7, AF7)>;
				bias-pull-up;
			};

			/omit-if-no-ref/ uart4_tx_pa0: uart4_tx_pa0 {
				pinmux = <STM32_PINMUX('A', 0, AF8)>;
				bias-pull-up;
			};

			/* USB */

			/omit-if-no-ref/ usb_dm_pa11: usb_dm_pa11 {
				pinmux = <STM32_PINMUX('A', 11, ANALOG)>;
			};

			/omit-if-no-ref/ usb_dp_pa12: usb_dp_pa12 {
				pinmux = <STM32_PINMUX('A', 12, ANALOG)>;
			};

			/omit-if-no-ref/ usb_noe_pa13: usb_noe_pa13 {
				pinmux = <STM32_PINMUX('A', 13, AF10)>;
			};

		};
	};
};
